# R7FA4W1AD register map
Vendor: Renesas; Series: RA4; File version: 1.0
CPU: CM4 r0p1, little endian, MPU, FPU, VTOR, 4 interrupt priority bits
Registers are 8-bit, read-write, reset 0x0 unless marked. A register's access mark holds for its fields unless they carry their own. Offsets are from the block's base; [hi:lo] are bit positions; {n}, {i} and the like mark numbered series.

## SLCDC — Segment LCD Controller/Driver
Base 0x40082000
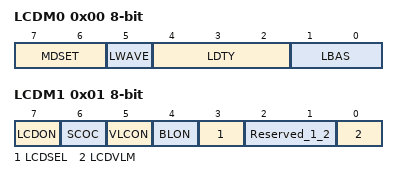
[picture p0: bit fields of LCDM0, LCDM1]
0x00 LCDM0 — LCD Mode Register 0
  [7:6] MDSET — LCD drive voltage generator selection
  [5] LWAVE — LCD display waveform selection
  [4:2] LDTY — Time Slice of LCD Display Select
  [1:0] LBAS — LCD Display Bias Method Select
0x01 LCDM1 — LCD Mode Register 1
  [7] LCDON — LCD Display Enable/Disable
  [6] SCOC — LCD Display Enable/Disable
  [5] VLCON — Voltage boost circuit or capacitor split circuit operation enable/disable
  [4] BLON — Display data area control
  [3] LCDSEL — Display data area control
  [2:1] Reserved_1_2 — These bits are read as 00. The write value should be 00.
  [0] LCDVLM — Voltage Boosting Pin Initial Value Switching Control
0x02 LCDC0 — LCD Clock Control Register 0
  [5:0] LCDC — LCD clock (LCDCL)
0x03 VLCD reset 0x4 — LCD Boost Level Control Register
  [4:0] VLCD — Reference Voltage(Contrast Adjustment) Select
{0x100+i} SEG{i} (i=0..53) — LCD Display Data Register {i}
  [7:0] SEG — LCD Display Data

## OPAMP — OperationalAmplifier
Base 0x40086000
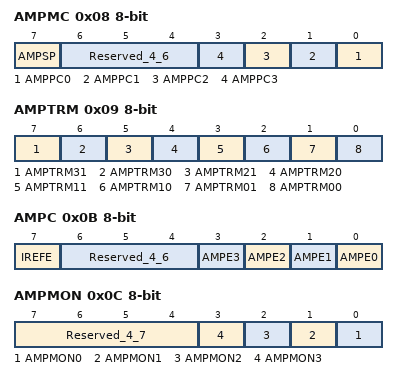
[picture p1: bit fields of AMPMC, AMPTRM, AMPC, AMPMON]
0x08 AMPMC — Operational amplifier mode control register
  [7] AMPSP — Operation mode selection
  [6:4] Reserved_4_6 — These bits are read as 000. The write value should be 000.
  [n] AMPPC{n} (n=0..3) — Operational amplifier precharge control status
0x09 AMPTRM — Operational amplifier trigger mode control register
  [7] AMPTRM31 — Operational amplifier function activation/stop trigger control
  [6] AMPTRM30 — Operational amplifier function activation/stop trigger control
  [5] AMPTRM21 — Operational amplifier function activation/stop trigger control
  [4] AMPTRM20 — Operational amplifier function activation/stop trigger control
  [3] AMPTRM11 — Operational amplifier function activation/stop trigger control
  [2] AMPTRM10 — Operational amplifier function activation/stop trigger control
  [1] AMPTRM01 — Operational amplifier function activation/stop trigger control
  [0] AMPTRM00 — Operational amplifier function activation/stop trigger control
0x0A AMPTRS — Operational Amplifier Activation Trigger Select Register
  [1:0] AMPTRS — ELC trigger selection Do not change the value of the AMPTRS register after setting the AMPTRM register.
0x0B AMPC — Operational amplifier control register
  [7] IREFE — Operation control of operational amplifier reference current circuit
  [6:4] Reserved_4_6 — These bits are read as 000. The write value should be 000.
  [n] AMPE{n} (n=0..3) — Operation control of operational amplifier(UNIT{n})
0x0C AMPMON ro — Operational amplifier monitor register
  [7:4] Reserved_4_7 — These bits are read as 0000.
  [n] AMPMON{n} (n=0..3) — Operational amplifier status(UNIT{n})

## DTC — Data Transfer Controller
Base 0x40005400
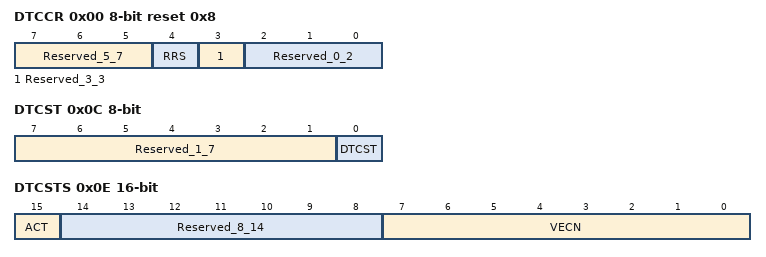
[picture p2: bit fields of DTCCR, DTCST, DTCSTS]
0x00 DTCCR reset 0x8 — DTC Control Register
  [7:5] Reserved_5_7 — These bits are read as 000. The write value should be 000.
  [4] RRS — DTC Transfer Information Read Skip Enable.
  [3] Reserved_3_3 — This bit is read as 1. The write value should be 1.
  [2:0] Reserved_0_2 — These bits are read as 000. The write value should be 000.
0x04 DTCVBR 32-bit — DTC Vector Base Register
  [31:0] DTCVBR — DTC Vector Base Address.Note: A value cannot be set in the lower,order 10 bits. These bits are fixed to 0.
0x0C DTCST — DTC Module Start Register
  [7:1] Reserved_1_7 — These bits are read as 0000000. The write value should be 0000000.
  [0] DTCST — DTC Module Start
0x0E DTCSTS 16-bit ro — DTC Status Register
  [15] ACT — DTC Active Flag
  [14:8] Reserved_8_14 — These bits are read as 0000000.
  [7:0] VECN — DTC,Activating Vector Number MonitoringThese bits indicate the vector number for the activating source when DTC transfer is in progress.The value is only valid if DTC transfer is in progress (the value of the ACT flag is 1)

## KINT — Key Interrupt Function
Base 0x40080000
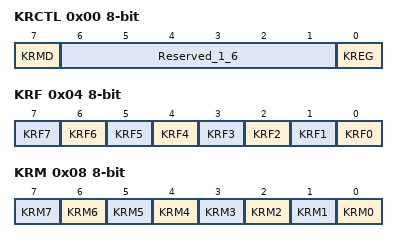
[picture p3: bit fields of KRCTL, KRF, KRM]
0x00 KRCTL — KEY Return Control Register
  [7] KRMD — Usage of Key Interrupt Flags(KR0 to KR7)
  [6:1] Reserved_1_6 — These bits are read as 000000. The write value should be 000000.
  [0] KREG — Detection Edge Selection (KRF0 to KRF7)
0x04 KRF write-0-clears read-modifies — KEY Return Flag Register
  [n] KRF{n} write-0-clears read-modifies (n=0..7) — Key interrupt flag {n}
0x08 KRM — KEY Return Mode Register
  [n] KRM{n} (n=0..7) — Key interrupt mode control {n}
